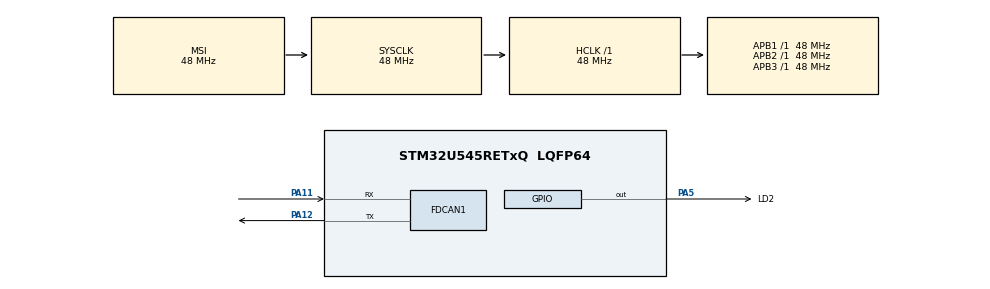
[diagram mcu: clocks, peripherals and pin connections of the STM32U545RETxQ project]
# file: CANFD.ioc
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CORTEX_M33_NS.userName=CORTEX_M33
FDCAN1.CalculateBaudRateNominal=500000
FDCAN1.CalculateTimeBitNominal=2000
FDCAN1.CalculateTimeQuantumNominal=125.0
FDCAN1.FrameFormat=FDCAN_FRAME_FD_BRS
FDCAN1.Mode=FDCAN_MODE_NORMAL
FDCAN1.NominalPrescaler=6
FDCAN1.NominalTimeSeg1=13
FDCAN1.NominalTimeSeg2=2
FDCAN1.TxFifoQueueMode=FDCAN_TX_QUEUE_OPERATION
Mcu.Family=STM32U5
Mcu.Name=STM32U545RETxQ
Mcu.Package=LQFP64
NVIC.FDCAN1_IT0_IRQn=true\:0\:0\:false\:false\:true\:true\:true\:true
NVIC.PriorityGroup=NVIC_PRIORITYGROUP_4
NVIC.TIM2_IRQn=true\:0\:0\:false\:false\:true\:true\:true\:true
PA11.Mode=FDCAN_Activate
PA11.Signal=FDCAN1_RX
PA12.Mode=FDCAN_Activate
PA12.Signal=FDCAN1_TX
PA5.GPIO_Label=LD2
PA5.Signal=GPIO_Output
ProjectManager.HeapSize=0x200
ProjectManager.StackSize=0x400
ProjectManager.TargetToolchain=STM32CubeIDE
RCC.ADCFreq_Value=16000000
RCC.AHBFreq_Value=48000000
RCC.APB1Freq_Value=48000000
RCC.APB1TimFreq_Value=48000000
RCC.APB2Freq_Value=48000000
RCC.APB2TimFreq_Value=48000000
RCC.APB3Freq_Value=48000000
RCC.CortexFreq_Value=48000000
RCC.DACCLockSelectionVirtual=RCC_DAC1CLKSOURCE_LSI
RCC.DACCLockSelectionVirtualString=RCC_DAC1CLKSOURCE_LSI
RCC.EPOD_VALUE=48000000
RCC.HCLKFreq_Value=48000000
RCC.HSE_VALUE=16000000
RCC.HSI48_VALUE=48000000
RCC.HSI_VALUE=16000000
RCC.LSE_VALUE=32768
RCC.LSIDIV_VALUE=32000
RCC.MSIClockRange=RCC_MSIRANGE_0
RCC.MSI_VALUE=48000000
RCC.PLL1Q=3
RCC.PLL2FRACN=0
RCC.PLL3FRACN=0
RCC.PLLFRACN=0
RCC.PLLM=3
RCC.PLLN=9
RCC.SYSCLKFreq_VALUE=48000000
RCC.USBFreq_Value=48000000
RCC.VCOOutputFreq_Value=144000000
TIM2.AutoReloadPreload=TIM_AUTORELOAD_PRELOAD_ENABLE
TIM2.PeriodNoDither=99
TIM2.Prescaler=47999
VP_LPBAMQUEUE_VS_QUEUE.Mode=QUEUEMODE
VP_LPBAM_VS_SIG1.Mode=SmartRun
VP_LPBAM_VS_SIG4.Mode=LPDMA1
VP_MEMORYMAP_VS_MEMORYMAP.Mode=CurAppReg
VP_PWR_VS_SECSignals.Mode=Security/Privilege
VP_TIM2_VS_ClockSourceINT.Mode=Internal
board=custom

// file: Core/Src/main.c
/* USER CODE BEGIN Header */
/**
  ******************************************************************************
  * @file           : main.c
  * @brief          : Main program body
  ******************************************************************************
  * @attention
  *
  * Copyright (c) 2026 STMicroelectronics.
  * All rights reserved.
  *
  * This software is licensed under terms that can be found in the LICENSE file
  * in the root directory of this software component.
  * If no LICENSE file comes with this software, it is provided AS-IS.
  *
  ******************************************************************************
  */
/* USER CODE END Header */
#include "main.h"

FDCAN_HandleTypeDef hfdcan1;

TIM_HandleTypeDef htim2;

void SystemClock_Config(void);
static void MX_GPIO_Init(void);
static void MX_TIM2_Init(void);

int main(void)
{

  /* MCU Configuration--------------------------------------------------------*/

  /* Reset of all peripherals, Initializes the Flash interface and the Systick. */
  HAL_Init();

  /* Configure the system clock */
  SystemClock_Config();

  /* Initialize all configured peripherals */
  MX_GPIO_Init();
  MX_FDCAN1_Init();
  MX_TIM2_Init();

  /* Infinite loop */
  while (1)
  {

  }
}

void SystemClock_Config(void)
{
  RCC_OscInitTypeDef RCC_OscInitStruct = {0};
  RCC_ClkInitTypeDef RCC_ClkInitStruct = {0};

  /** Configure the main internal regulator output voltage
  */
  if (HAL_PWREx_ControlVoltageScaling(PWR_REGULATOR_VOLTAGE_SCALE3) != HAL_OK)
  {
    Error_Handler();
  }

  /** Initializes the CPU, AHB and APB buses clocks
  */
  RCC_OscInitStruct.OscillatorType = RCC_OSCILLATORTYPE_MSI;
  RCC_OscInitStruct.MSIState = RCC_MSI_ON;
  RCC_OscInitStruct.MSICalibrationValue = RCC_MSICALIBRATION_DEFAULT;
  RCC_OscInitStruct.MSIClockRange = RCC_MSIRANGE_0;
  RCC_OscInitStruct.PLL.PLLState = RCC_PLL_ON;
  RCC_OscInitStruct.PLL.PLLSource = RCC_PLLSOURCE_MSI;
  RCC_OscInitStruct.PLL.PLLMBOOST = RCC_PLLMBOOST_DIV4;
  RCC_OscInitStruct.PLL.PLLM = 3;
  RCC_OscInitStruct.PLL.PLLN = 9;
  RCC_OscInitStruct.PLL.PLLP = 2;
  RCC_OscInitStruct.PLL.PLLQ = 3;
  RCC_OscInitStruct.PLL.PLLR = 2;
  RCC_OscInitStruct.PLL.PLLRGE = RCC_PLLVCIRANGE_1;
  RCC_OscInitStruct.PLL.PLLFRACN = 0;
  if (HAL_RCC_OscConfig(&RCC_OscInitStruct) != HAL_OK)
  {
    Error_Handler();
  }

  /** Initializes the CPU, AHB and APB buses clocks
  */
  RCC_ClkInitStruct.ClockType = RCC_CLOCKTYPE_HCLK|RCC_CLOCKTYPE_SYSCLK
                              |RCC_CLOCKTYPE_PCLK1|RCC_CLOCKTYPE_PCLK2
                              |RCC_CLOCKTYPE_PCLK3;
  RCC_ClkInitStruct.SYSCLKSource = RCC_SYSCLKSOURCE_MSI;
  RCC_ClkInitStruct.AHBCLKDivider = RCC_SYSCLK_DIV1;
  RCC_ClkInitStruct.APB1CLKDivider = RCC_HCLK_DIV1;
  RCC_ClkInitStruct.APB2CLKDivider = RCC_HCLK_DIV1;
  RCC_ClkInitStruct.APB3CLKDivider = RCC_HCLK_DIV1;

  if (HAL_RCC_ClockConfig(&RCC_ClkInitStruct, FLASH_LATENCY_1) != HAL_OK)
  {
    Error_Handler();
  }
}

static void MX_TIM2_Init(void)
{

  TIM_ClockConfigTypeDef sClockSourceConfig = {0};
  TIM_MasterConfigTypeDef sMasterConfig = {0};

  htim2.Instance = TIM2;
  htim2.Init.Prescaler = 47999;
  htim2.Init.CounterMode = TIM_COUNTERMODE_UP;
  htim2.Init.Period = 99;
  htim2.Init.ClockDivision = TIM_CLOCKDIVISION_DIV1;
  htim2.Init.AutoReloadPreload = TIM_AUTORELOAD_PRELOAD_ENABLE;
  if (HAL_TIM_Base_Init(&htim2) != HAL_OK)
  {
    Error_Handler();
  }
  sClockSourceConfig.ClockSource = TIM_CLOCKSOURCE_INTERNAL;
  if (HAL_TIM_ConfigClockSource(&htim2, &sClockSourceConfig) != HAL_OK)
  {
    Error_Handler();
  }
  sMasterConfig.MasterOutputTrigger = TIM_TRGO_RESET;
  sMasterConfig.MasterSlaveMode = TIM_MASTERSLAVEMODE_DISABLE;
  if (HAL_TIMEx_MasterConfigSynchronization(&htim2, &sMasterConfig) != HAL_OK)
  {
    Error_Handler();
  }
  /* USER CODE BEGIN TIM2_Init 2 */
  /* Start TIM2 base timer in interrupt mode */
  if (HAL_TIM_Base_Start_IT(&htim2) != HAL_OK)
  {
    Error_Handler();
  }
  /* USER CODE END TIM2_Init 2 */

}

static void MX_GPIO_Init(void)
{
  GPIO_InitTypeDef GPIO_InitStruct = {0};

  /* GPIO Ports Clock Enable */
  __HAL_RCC_GPIOA_CLK_ENABLE();

  /*Configure GPIO pin Output Level */
  HAL_GPIO_WritePin(LD2_GPIO_Port, LD2_Pin, GPIO_PIN_RESET);

  /*Configure GPIO pin : LD2_Pin */
  GPIO_InitStruct.Pin = LD2_Pin;
  GPIO_InitStruct.Mode = GPIO_MODE_OUTPUT_PP;
  GPIO_InitStruct.Pull = GPIO_NOPULL;
  GPIO_InitStruct.Speed = GPIO_SPEED_FREQ_LOW;
  HAL_GPIO_Init(LD2_GPIO_Port, &GPIO_InitStruct);

}

void Error_Handler(void)
{
  __disable_irq();
  while (1)
  {
  }
}
